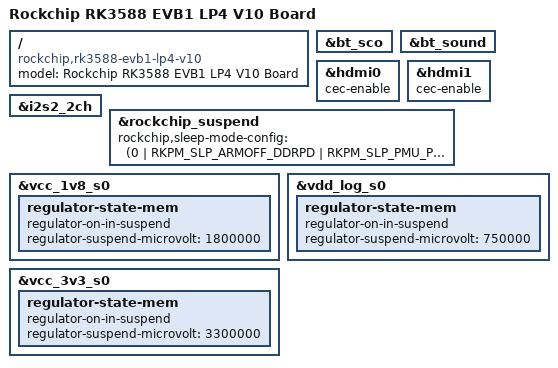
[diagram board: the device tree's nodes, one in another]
// SPDX-License-Identifier: (GPL-2.0+ OR MIT)
/*
 * Copyright (c) 2021 Rockchip Electronics Co., Ltd.
 *
 */

/dts-v1/;

#include "rk3588-evb1-lp4.dtsi"
#include "rk3588-evb1-imx415.dtsi"
#include "rk3588-android.dtsi"

/ {
	model = "Rockchip RK3588 EVB1 LP4 V10 Board";
	compatible = "rockchip,rk3588-evb1-lp4-v10", "rockchip,rk3588";
};

&bt_sco {
	status = "okay";
};

&bt_sound {
	status = "okay";
};

&hdmi0 {
	cec-enable;
};

&hdmi1 {
	cec-enable;
};

&i2s2_2ch {
	status = "okay";
};

&rockchip_suspend {
	rockchip,sleep-mode-config = <
		(0
		| RKPM_SLP_ARMOFF_DDRPD
		| RKPM_SLP_PMU_PMUALIVE_32K
		| RKPM_SLP_PMU_DIS_OSC
		| RKPM_SLP_32K_EXT
		)
	>;
};

&vcc_1v8_s0 {
	regulator-state-mem {
		regulator-on-in-suspend;
		regulator-suspend-microvolt = <1800000>;
	};
};

&vcc_3v3_s0 {
	regulator-state-mem {
		regulator-on-in-suspend;
		regulator-suspend-microvolt = <3300000>;
	};
};

&vdd_log_s0 {
	regulator-state-mem {
		regulator-on-in-suspend;
		regulator-suspend-microvolt = <750000>;
	};
};
